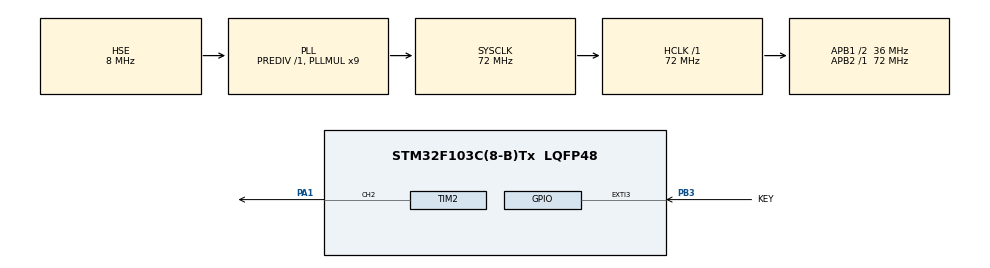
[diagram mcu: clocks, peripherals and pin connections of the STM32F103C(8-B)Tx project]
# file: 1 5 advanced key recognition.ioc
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Mcu.Family=STM32F1
Mcu.Name=STM32F103C(8-B)Tx
Mcu.Package=LQFP48
NVIC.EXTI3_IRQn=true\:0\:0\:false\:false\:true\:true\:true\:true
NVIC.PriorityGroup=NVIC_PRIORITYGROUP_4
PA1.Signal=S_TIM2_CH2
PA13.Mode=Serial_Wire
PA13.Signal=SYS_JTMS-SWDIO
PA14.Mode=Serial_Wire
PA14.Signal=SYS_JTCK-SWCLK
PB3.GPIO_Label=KEY
PB3.GPIO_ModeDefaultEXTI=GPIO_MODE_IT_FALLING
PB3.GPIO_PuPd=GPIO_PULLUP
PB3.Signal=GPXTI3
PC14-OSC32_IN.Mode=LSE-External-Oscillator
PC14-OSC32_IN.Signal=RCC_OSC32_IN
PC15-OSC32_OUT.Mode=LSE-External-Oscillator
PC15-OSC32_OUT.Signal=RCC_OSC32_OUT
PD0-OSC_IN.Mode=HSE-External-Oscillator
PD0-OSC_IN.Signal=RCC_OSC_IN
PD1-OSC_OUT.Mode=HSE-External-Oscillator
PD1-OSC_OUT.Signal=RCC_OSC_OUT
ProjectManager.HeapSize=0x200
ProjectManager.StackSize=0x400
ProjectManager.TargetToolchain=MDK-ARM V5.32
RCC.AHBFreq_Value=72000000
RCC.APB1CLKDivider=RCC_HCLK_DIV2
RCC.APB1Freq_Value=36000000
RCC.APB1TimFreq_Value=72000000
RCC.APB2Freq_Value=72000000
RCC.APB2TimFreq_Value=72000000
RCC.HCLKFreq_Value=72000000
RCC.PLLMUL=RCC_PLL_MUL9
RCC.PLLSourceVirtual=RCC_PLLSOURCE_HSE
RCC.SYSCLKFreq_VALUE=72000000
RCC.SYSCLKSource=RCC_SYSCLKSOURCE_PLLCLK
RCC.USBFreq_Value=72000000
SH.S_TIM2_CH2.0=TIM2_CH2,PWM Generation2 CH2
TIM2.AutoReloadPreload=TIM_AUTORELOAD_PRELOAD_ENABLE
TIM2.Channel-PWM\ Generation2\ CH2=TIM_CHANNEL_2
TIM2.Period=20000
TIM2.Prescaler=72
board=custom

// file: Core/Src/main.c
/* USER CODE BEGIN Header */
/**
  ******************************************************************************
  * @file           : main.c
  * @brief          : Main program body
  ******************************************************************************
  * @attention
  *
  * Copyright (c) 2025 STMicroelectronics.
  * All rights reserved.
  *
  * This software is licensed under terms that can be found in the LICENSE file
  * in the root directory of this software component.
  * If no LICENSE file comes with this software, it is provided AS-IS.
  *
  ******************************************************************************
  */
/* USER CODE END Header */
#include "main.h"
#include "tim.h"
#include "gpio.h"

/* USER CODE BEGIN PV */
	uint16_t press=0;
	uint16_t press_mode=0;      //0:初始,1:单击,2:双击,3:长按
	uint32_t last_time = 0;
	uint32_t current_time = 0;
	uint32_t press_time = 0;
	uint32_t press_time_sec = 0;
	uint32_t release_time = 0;
	uint32_t waiting_time = 0;
	uint32_t end_time = 0;
	typedef enum{
	key_vacant=0,
	key_true_press,
	key_single,
	key_release,
	key_press_shake,
	key_press_shake_sec,
	key_release_shake,
	key_record_time,
	key_end,
	}key_state_t;
	volatile key_state_t key_state = key_vacant;
	typedef enum{
	servo_free=0,
	servo_busy,
	servo_define_time,
	}servo_state_t;
	volatile servo_state_t servo_state = servo_free;
/* USER CODE END PV */

void SystemClock_Config(void);
/* USER CODE BEGIN PFP */
	void key_sm(void);
	void servo_sm(void);
/* USER CODE END PFP */

int main(void)
{

  /* MCU Configuration--------------------------------------------------------*/

  /* Reset of all peripherals, Initializes the Flash interface and the Systick. */
  HAL_Init();

  /* Configure the system clock */
  SystemClock_Config();

  /* Initialize all configured peripherals */
  MX_GPIO_Init();
  MX_TIM2_Init();
  /* USER CODE BEGIN 2 */
	HAL_TIM_PWM_Start(&htim2,TIM_CHANNEL_2);
	current_time = HAL_GetTick();
  /* USER CODE END 2 */

  /* Infinite loop */
  /* USER CODE BEGIN WHILE */
  while (1)
  {
	  key_sm();
	  servo_sm();
    /* USER CODE END WHILE */

  }
}

void SystemClock_Config(void)
{
  RCC_OscInitTypeDef RCC_OscInitStruct = {0};
  RCC_ClkInitTypeDef RCC_ClkInitStruct = {0};

  /** Initializes the RCC Oscillators according to the specified parameters
  * in the RCC_OscInitTypeDef structure.
  */
  RCC_OscInitStruct.OscillatorType = RCC_OSCILLATORTYPE_HSE;
  RCC_OscInitStruct.HSEState = RCC_HSE_ON;
  RCC_OscInitStruct.HSEPredivValue = RCC_HSE_PREDIV_DIV1;
  RCC_OscInitStruct.HSIState = RCC_HSI_ON;
  RCC_OscInitStruct.PLL.PLLState = RCC_PLL_ON;
  RCC_OscInitStruct.PLL.PLLSource = RCC_PLLSOURCE_HSE;
  RCC_OscInitStruct.PLL.PLLMUL = RCC_PLL_MUL9;
  if (HAL_RCC_OscConfig(&RCC_OscInitStruct) != HAL_OK)
  {
    Error_Handler();
  }

  /** Initializes the CPU, AHB and APB buses clocks
  */
  RCC_ClkInitStruct.ClockType = RCC_CLOCKTYPE_HCLK|RCC_CLOCKTYPE_SYSCLK
                              |RCC_CLOCKTYPE_PCLK1|RCC_CLOCKTYPE_PCLK2;
  RCC_ClkInitStruct.SYSCLKSource = RCC_SYSCLKSOURCE_PLLCLK;
  RCC_ClkInitStruct.AHBCLKDivider = RCC_SYSCLK_DIV1;
  RCC_ClkInitStruct.APB1CLKDivider = RCC_HCLK_DIV2;
  RCC_ClkInitStruct.APB2CLKDivider = RCC_HCLK_DIV1;

  if (HAL_RCC_ClockConfig(&RCC_ClkInitStruct, FLASH_LATENCY_2) != HAL_OK)
  {
    Error_Handler();
  }
}

/* USER CODE BEGIN 4 */
void HAL_GPIO_EXTI_Callback(uint16_t GPIO_Pin)
{
  if (GPIO_Pin == KEY_Pin)
  {
    press = 1;
  }
}

void key_sm(void){
	current_time = HAL_GetTick();
	if (current_time - last_time < 5){
		return;
	}
    last_time = current_time;    //每5ms扫描一次

	switch(key_state){
	case (key_vacant):{
		if(press == 1){
			press_time = current_time;
			key_state=key_press_shake;
			press=0;
			}
		break;
		}                      //记录按键按下时间并跳转
	case (key_press_shake):{
		if(current_time - press_time >=20){
				if(HAL_GPIO_ReadPin(KEY_GPIO_Port,KEY_Pin)== GPIO_PIN_RESET){
					key_state=key_true_press;
				}
				else{
					key_state=key_vacant;
				}
			}
		break;
	}                            //消抖并判断是否真正按下
	case (key_true_press):{
		if(HAL_GPIO_ReadPin(KEY_GPIO_Port,KEY_Pin)== GPIO_PIN_SET){
			release_time=current_time;
			key_state=key_release_shake;
		}
	break;
	}                           //记录按键松开时间并跳转
	case (key_release_shake):{
		if(current_time - release_time >=20){
				if(HAL_GPIO_ReadPin(KEY_GPIO_Port,KEY_Pin)== GPIO_PIN_SET){
					key_state=key_release;
				}
				else{
					key_state=key_true_press;
				}
			}
		break;
	}                         //消抖并判断是否真正松开
	case (key_release):{
		if(release_time - press_time >=700){
			press_mode=3;
			key_state=key_record_time;
		}
		else{
			key_state=key_single;
		}
		break;
		}                        //判断是否为长按
	case(key_single):{
		if(current_time - release_time <= 350){
			if(HAL_GPIO_ReadPin(KEY_GPIO_Port,KEY_Pin)== GPIO_PIN_RESET){
			press_time_sec=current_time;
			key_state=key_press_shake_sec;
			}
		}
		else {
			press_mode=1;
			key_state=key_record_time;
		}
		break;
		}                               //判断是否在双击时间内按下了第二次按键,否则为单击
	case (key_press_shake_sec):{
		if(current_time - press_time_sec >=20){
				if(HAL_GPIO_ReadPin(KEY_GPIO_Port,KEY_Pin)== GPIO_PIN_RESET){
					press_mode=2;
					key_state=key_record_time;
					}                               //消抖并判断第二次是否真的按下,若按下则为双击
				else{
					key_state=key_single;
				}
			}
		break;
	}
	case (key_record_time):{
		end_time=HAL_GetTick();
		key_state = key_end;
		break;
	}
	case (key_end):{
		current_time = HAL_GetTick();
		if(current_time - end_time >=500){
			key_state = key_vacant;
		}
		break;
	}                  //提供500ms的时间供所有设置复原
	}
}
void servo_sm(void){
	switch (servo_state){
		case (servo_free):{
			if(press_mode == 1){
		__HAL_TIM_SET_COMPARE(&htim2,TIM_CHANNEL_2,500);
		press_mode=0;
		servo_state=servo_define_time;
		}
		if(press_mode == 2){
			__HAL_TIM_SET_COMPARE(&htim2,TIM_CHANNEL_2,1500);
			press_mode=0;
			servo_state=servo_define_time;
			}
		if(press_mode == 3){
			__HAL_TIM_SET_COMPARE(&htim2,TIM_CHANNEL_2,2500);
			press_mode=0;
			servo_state=servo_define_time;
			}
	break;
		}                         //单击转到-90°,双击转到0°,长按转到90°
		case (servo_define_time):{
			waiting_time=current_time;
			servo_state=servo_busy;
			break;
		}
		case (servo_busy):{
			current_time = HAL_GetTick();
			if(current_time - waiting_time >=200){
				servo_state=servo_free;
			}
			break;                      //使舵机完成转向
		}
	}
}
/* USER CODE END 4 */

void Error_Handler(void)
{
  __disable_irq();
  while (1)
  {
  }
}
